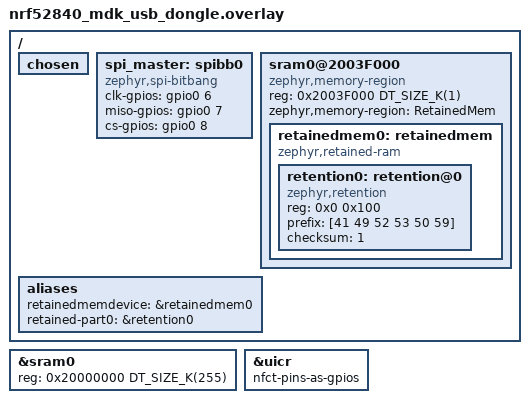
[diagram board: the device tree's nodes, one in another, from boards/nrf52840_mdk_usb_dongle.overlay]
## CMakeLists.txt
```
# Copyright (c) 2026 Arne Wendt (@bitmeal)
# SPDX-License-Identifier: MPL-2.0

cmake_minimum_required(VERSION 3.20.0)

### Zephyr
find_package(Zephyr REQUIRED HINTS $ENV{ZEPHYR_BASE})

## configure project
project(sks_airspy_community)

## check if we are building with sysbuild
test_sysbuild(REQUIRED)


### APP
# app sources
target_sources(app PRIVATE src/main.c)
target_sources(app PRIVATE src/common.c)
target_sources(app PRIVATE src/resource_manager.c)
target_sources(app PRIVATE src/settings.c)
target_sources(app PRIVATE src/bluetooth.c)
target_sources(app PRIVATE src/retained.c)
target_sources(app PRIVATE src/spi.c)
target_sources(app PRIVATE src/zbus_com.c)
target_sources(app PRIVATE src/sensor.c)

if(CONFIG_AIRSPY_ANT)
    target_sources(app PRIVATE src/ant.c)

    # ant tpms profile sources
    target_sources(app PRIVATE src/ant_profiles/ant_tpms/ant_tpms.c)
    target_sources(app PRIVATE src/ant_profiles/ant_tpms/pages/ant_tpms_page_1.c)
    target_sources(app PRIVATE src/ant_profiles/ant_tpms/pages/ant_tpms_page_16.c)
    target_sources(app PRIVATE src/ant_profiles/ant_common/pages/ant_common_page_82.c)
endif()

## include paths
target_include_directories(app PRIVATE include/)
zephyr_library_include_directories(.)
```

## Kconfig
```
# Copyright (c) 2026 Arne Wendt (@bitmeal)
# SPDX-License-Identifier: MPL-2.0


config AIRSPY_DEFAULTS
    bool
    default y
    select HW_ID_LIBRARY
    select PM_DEVICE
    select PM_DEVICE_RUNTIME
    # select POWEROFF
    select ZBUS
    select GPIO
    select SPI
    select SPI_BITBANG
    select RTC
    select RTC_EMUL
    select NVS
    select CRC
    select SETTINGS
    select SETTINGS_RUNTIME
    select MPU_ALLOW_FLASH_WRITE
    select RETENTION
    select RETAINED_MEM
    select RETAINED_MEM_ZEPHYR_RAM


if AIRSPY_DEFAULTS

choice HW_ID_LIBRARY_SOURCE
    default HW_ID_LIBRARY_SOURCE_DEVICE_ID
endchoice

choice SETTINGS_BACKEND
    default SETTINGS_NVS
endchoice

config NCS_APPLICATION_BOOT_BANNER_STRING
    default "AIRSPY Community"

config RESET_ON_FATAL_ERROR
    default n

config BOARD_SERIAL_BACKEND_CDC_ACM
    default n

config SPI_NRFX
    default n

endif # AIRSPY_DEFAULTS

# ---

config AIRSPY_SIZE_OPTIMIZATIONS
    bool
    default y

if AIRSPY_SIZE_OPTIMIZATIONS

choice COMPILER_OPTIMIZATIONS
    default SIZE_OPTIMIZATIONS
endchoice

config BT_USER_PHY_UPDATE
    default n

config BT_PHY_UPDATE
    default n

config NET_BUF_POOL_USAGE
    default n

config LOG_RUNTIME_FILTERING
    default n
    
endif # AIRSPY_SIZE_OPTIMIZATIONS

# ---

config AIRSPY_ANT
    bool "enable ANT communiction; disable for debugging or development if no ANT SDK is available"
    default y
    select ANT
    select ANT_EVALUATION_KEY
    select ANT_CHANNEL_CONFIG
    select ANT_KEY_MANAGER
    select ANT_COMMON

if AIRSPY_ANT

config HEAP_MEM_POOL_SIZE
    default 2048
    # default 4096

config ANT_TOTAL_CHANNELS_ALLOCATED
    default 1

endif # AIRSPY_ANT

# ---

config AIRSPY_DFU_COMPAT_PADDING
    bool "0x400 pm static mcuboot padding"
    default y
    help
        force compatibility with previously set values in pm_static.yml
        allows OTA DFU of devices using MCUboot variants build from partition manager configuration

if AIRSPY_DFU_COMPAT_PADDING

config ROM_START_OFFSET
	default 0x400 if BOOTLOADER_MCUBOOT && USE_DT_CODE_PARTITION

endif # AIRSPY_DFU_COMPAT_PADDING

# TODO: BT dependency

config AIRSPY_DFU
    bool
    default y
    select MPU_ALLOW_FLASH_WRITE
    select MCUMGR
    select FLASH
    select STREAM_FLASH
    select FLASH_MAP
    select NET_BUF
    select ZCBOR
    select IMG_MANAGER
    select MCUMGR
    select MCUMGR_MGMT_NOTIFICATION_HOOKS
    select MCUMGR_GRP_IMG
    select MCUMGR_GRP_IMG_STATUS_HOOKS
    select MCUMGR_GRP_IMG_SLOT_INFO
    select MCUMGR_GRP_OS
    select MCUMGR_GRP_OS_MCUMGR_PARAMS
    select MCUMGR_GRP_OS_ECHO
    select MCUMGR_GRP_OS_INFO
    select MCUMGR_GRP_OS_DATETIME
    select MCUMGR_GRP_OS_DATETIME_MS
    select MCUMGR_GRP_OS_BOOTLOADER_INFO
    # select MCUMGR_GRP_OS_INFO_BUILD_DATE_TIME
    select MCUMGR_GRP_ENUM
    select MCUMGR_GRP_ENUM_DETAILS
    select MCUMGR_GRP_ENUM_DETAILS_NAME
    select MCUMGR_GRP_SETTINGS
    select MCUMGR_GRP_SETTINGS_ACCESS_HOOK
    select MCUMGR_TRANSPORT_BT
    select MCUMGR_TRANSPORT_BT_CONN_PARAM_CONTROL
    select MCUMGR_TRANSPORT_BT_REASSEMBLY

if AIRSPY_DFU

config BT_L2CAP_TX_MTU
    default 498

config BT_BUF_ACL_RX_SIZE
    default 502

config BT_BUF_ACL_TX_SIZE
    default 502

config BT_CTLR_DATA_LENGTH_MAX
    default 251

config MCUMGR_GRP_ZBASIC_STORAGE_ERASE
    default n

config MCUMGR_TRANSPORT_NETBUF_SIZE
    default 2475

config MCUMGR_TRANSPORT_WORKQUEUE_STACK_SIZE
    default 4608

# set high to transfer signature keys as settings
config MCUMGR_GRP_SETTINGS_VALUE_LEN
    default 512

config MAIN_STACK_SIZE
    default 2176
    # default 2048
config SYSTEM_WORKQUEUE_STACK_SIZE
    default 2304

endif # AIRSPY_DFU

# ---

config AIRSPY_BT
    bool
    default y
    select BT
    select BT_DEVICE_NAME_DYNAMIC
    select BT_PERIPHERAL
    select BT_DIS
    select BT_DIS_MODEL_NUMBER
    select BT_DIS_MANUF_NAME
    # select BT_DIS_SERIAL_NUMBER
    select BT_DIS_FW_REV
    # select BT_DIS_HW_REV
    select BT_DIS_SW_REV
    select BT_BAS

if AIRSPY_BT

config BT_DEVICE_NAME
    default "AIRSPY Community"

config BT_DEVICE_NAME_MAX
    default 23

config BT_DEVICE_APPEARANCE
    # 0x0559 / 1369 Vehicle Tire Pressure Sensor
    # 0x0480 / 1152 Generic Cycling
    default 1152

config BT_DIS_PNP
    default n

config BT_DIS_MODEL_NUMBER_STR
    default "Airspy"

config BT_DIS_MANUF_NAME_STR
    default "SKS"

# config BT_DIS_SERIAL_NUMBER_STR
#     default "Zephyr Serial"

config BT_DIS_FW_REV_STR
    default "Zephyr"

# config BT_DIS_HW_REV_STR
#     default "Zephyr Hardware"

config BT_DIS_SW_REV_STR
    default "Community"

config BT_MAX_CONN
    default 1

config BT_CTLR_LE_PING
    default n

endif # AIRSPY_BT

# ---
# TODO: depends RTT
# TODO: depends BT
# TODO: enable log, or enable log by enabling individual backends?

config AIRSPY_LOG
    bool
    default y
    select LOG
    select LOG_BACKEND_BLE
    select LOG_BACKEND_RTT
    select USE_SEGGER_RTT

if AIRSPY_LOG

choice LOG_MODE
    default LOG_MODE_DEFERRED
endchoice

# NUS logging requirement
config LOG_PROCESS_THREAD_STACK_SIZE
    default 2048

# disable duplicate log messages on RTT
config LOG_BACKEND_UART
    default n

endif # AIRSPY_LOG

# ---

source "Kconfig.zephyr"
```

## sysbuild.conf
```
# Copyright (c) 2026 Arne Wendt (@bitmeal)
# SPDX-License-Identifier: MPL-2.0

## MCUBoot bootloader config
SB_CONFIG_BOOTLOADER_MCUBOOT=y
SB_CONFIG_MCUBOOT_MODE_SWAP_USING_MOVE=y
# SB_CONFIG_BOOT_SIGNATURE_TYPE_RSA=y
# SB_CONFIG_BOOT_SIGNATURE_KEY_FILE="\${APP_DIR}/mcuboot.pem"

## build system configuration
# use partitions from device tree fstab.dtsi
SB_CONFIG_PARTITION_MANAGER=n

SB_CONFIG_WARN_EXPERIMENTAL=n

## output artifacts
SB_CONFIG_DFU_ZIP=y
# # generate merged.hex; currently broken in v3.2.4 with sysbuild; workaround in ./sysbuild/CMakeLists.txt
# SB_CONFIG_MERGED_HEX_FILES=y
```

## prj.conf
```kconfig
# Copyright (c) 2026 Arne Wendt (@bitmeal)
# SPDX-License-Identifier: MPL-2.0

CONFIG_WARN_EXPERIMENTAL=n
```

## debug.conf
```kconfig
# Copyright (c) 2026 Arne Wendt (@bitmeal)
# SPDX-License-Identifier: MPL-2.0

# CONFIG_AIRSPY_ANT=n

CONFIG_THREAD_NAME=y
CONFIG_THREAD_STACK_INFO=y
CONFIG_DEBUG=y
CONFIG_DEBUG_THREAD_INFO=y

## does not fit in flash with ANT stack
# CONFIG_DEBUG_OPTIMIZATIONS=y
```

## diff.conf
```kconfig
CONFIG_LOG=y
CONFIG_MCUBOOT_GENERATE_UNSIGNED_IMAGE=y
CONFIG_NCS_MCUBOOT_IN_BUILD=y
CONFIG_BOOTLOADER_MCUBOOT=y
CONFIG_USE_SEGGER_RTT=y
CONFIG_BOARD_HAS_NRF5_BOOTLOADER=n
CONFIG_GPIO_AS_PINRESET=y
CONFIG_NFCT_PINS_AS_GPIOS=y
CONFIG_RTT_CONSOLE=y
CONFIG_LOG_BACKEND_UART=n
```

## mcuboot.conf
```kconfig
# CONFIG_BOOT_VALIDATE_SLOT0=n

# crypto
# default (mbedtls)
# CONFIG_BOOT_SIGNATURE_TYPE_RSA=y
# tinycrypt:
# CONFIG_BOOT_SIGNATURE_TYPE_ECDSA_P256=y
# CONFIG_BOOT_SIGNATURE_TYPE_NONE=y

# 512kB flash; two images (each < 256kB); sector size 0x1000 / 4096B
# CONFIG_BOOT_MAX_IMG_SECTORS=64
# 52840 devel board
CONFIG_BOOT_MAX_IMG_SECTORS=128

# mcuboot
CONFIG_MCUBOOT_SERIAL=n

# peripherals/IO
CONFIG_GPIO=n
CONFIG_SERIAL=n
CONFIG_USE_SEGGER_RTT=n
CONFIG_CONSOLE=n
CONFIG_UART_CONSOLE=n
CONFIG_RTT_CONSOLE=n

# logging
CONFIG_LOG=n
CONFIG_BOOT_BANNER=n
CONFIG_MCUBOOT_BOOT_BANNER=n
CONFIG_NCS_BOOT_BANNER=n
```

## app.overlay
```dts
/*
 * Copyright (c) 2026 Arne Wendt (@bitmeal)
 * SPDX-License-Identifier: MPL-2.0
 */

 / {
    chosen {
        /delete-property/ zephyr,code-partition;
        zephyr,code-partition = &slot0_partition;

        /delete-property/ zephyr,console;
		zephyr,console = &rtt0;
    };

	rtt0: rtt_chan0 {
		compatible = "segger,rtt-uart";
		status = "okay";
	};

    rtc_emul: rtc-emul {
		compatible = "zephyr,rtc-emul";
		alarms-count = < 1 >;
	};

	aliases {
		rtc = &rtc_emul;
	};
};

// Include flash partition table.
#include "fstab.dtsi"
```

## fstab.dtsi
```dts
/*
 * Copyright (c) 2026 Arne Wendt (@bitmeal)
 * SPDX-License-Identifier: MPL-2.0
 */

&flash0 {
    /delete-node/ partitions;
};

&flash0 {
    partitions {
        compatible = "fixed-partitions";
        #address-cells = <1>;
        #size-cells = <1>;

        boot_partition: partition@0 {
            label = "mcuboot";
            reg = <0x00000000 0x00006000>;
            read-only;
        };

        slot0_partition: partition@6000 {
            label = "image-0";
            reg = <0x00006000 0x0003c000>;
        };
		
        slot1_partition: partition@42000 {
            label = "image-1";
            reg = <0x00042000 0x0003c000>;
        };

        storage_partition: partition@7e000 {
            label = "storage";
            reg = <0x0007e000 0x00002000>;
        };
    };
};
```

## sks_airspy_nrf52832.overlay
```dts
/*
 * Copyright (c) 2025 Arne Wendt (@bitmeal)
 * SPDX-License-Identifier: MPL-2.0
 */

// / {
// 	spi_master: spibb0 {
// 		compatible = "zephyr,spi-bitbang";
// 		status = "okay";
		
// 		#address-cells = <1>;
// 		#size-cells = <0>;
	
// 		clk-gpios = <&gpio0 19 GPIO_ACTIVE_HIGH>;
// 		miso-gpios = <&gpio0 15 0>;

// 		// interrupt pin
// 		cs-gpios = <&gpio0 22 GPIO_ACTIVE_LOW>;
// 	};
// };

// / {
//     chosen {
//         /* Directs Zephyr to link your application text section to the primary slot */
//         zephyr,code-partition = &slot0_partition;
//         // zephyr,code-partition = &slot0_app_partition;
//     };
// };

// &flash0 {
//     /delete-node/ partitions;
// };

// &flash0 {
//     partitions {
//         compatible = "fixed-partitions";
//         #address-cells = <1>;
//         #size-cells = <1>;

//         /* 0x00000 to 0x06000: MCUboot Bootloader (24 KB) */
//         boot_partition: partition@0 {
//             label = "mcuboot";
//             reg = <0x00000000 0x00006000>;
//             read-only;
//         };

//         /* 0x06000 to 0x42000: Primary Slot (240 KB total) */
//         slot0_partition: partition@6000 {
//             label = "image-0";
//             reg = <0x00006000 0x0003c000>;
//         };
		
		
//         // /* 0x06400 to 0x42000: Primary Slot App  */
// 		// slot0_app_partition: partition@6400 {
//         //     label = "image-0-app";
//         //     reg = <0x00006400 0x0003bc00>;
//         // };

//         /* 0x42000 to 0x7E000: Secondary Upgrade Slot (240 KB total) */
//         slot1_partition: partition@42000 {
//             label = "image-1";
//             reg = <0x00042000 0x0003c000>;
//         };

//         /* 0x7E000 to 0x80000: Zephyr Settings Subsystem Storage (8 KB) */
//         storage_partition: partition@7e000 {
//             label = "storage";
//             reg = <0x0007e000 0x00002000>;
//         };
//     };
// };
```

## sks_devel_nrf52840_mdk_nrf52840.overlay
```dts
/*
 * Copyright (c) 2025 Arne Wendt (@bitmeal)
 * SPDX-License-Identifier: MPL-2.0
 */

/ {
	spi_master: spibb0 {
		compatible = "zephyr,spi-bitbang";
		status = "okay";
		
		#address-cells = <1>;
		#size-cells = <0>;
	
		clk-gpios = <&gpio0 6 GPIO_ACTIVE_HIGH>;
		miso-gpios = <&gpio0 7 0>;

		// interrupt pin
		cs-gpios = <&gpio0 8 GPIO_ACTIVE_LOW>;
	};
};
```

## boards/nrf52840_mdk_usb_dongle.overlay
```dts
/*
 * Copyright (c) 2026 Arne Wendt (@bitmeal)
 * SPDX-License-Identifier: MPL-2.0
 */

/ {
	chosen {
		// /delete-property/ zephyr,console;
		// zephyr,console = &rtt0;

		// /delete-property/ zephyr,code-partition;
        	// zephyr,code-partition = &slot0_partition;
	};

	spi_master: spibb0 {
		compatible = "zephyr,spi-bitbang";
		status = "okay";

		#address-cells = <1>;
		#size-cells = <0>;

		clk-gpios = <&gpio0 6 GPIO_ACTIVE_HIGH>;
		miso-gpios = <&gpio0 7 GPIO_ACTIVE_HIGH>;

		// interrupt pin:
		// depending on model, active high or low! configured at runtime
		cs-gpios = <&gpio0 8 GPIO_ACTIVE_HIGH>;
	};

	sram0@2003F000 {
		compatible = "zephyr,memory-region", "mmio-sram";
		reg = <0x2003F000 DT_SIZE_K(1)>;
		zephyr,memory-region = "RetainedMem";
		status = "okay";

		retainedmem0: retainedmem  {
			compatible = "zephyr,retained-ram";
			status = "okay";

                        #address-cells = <1>;
                        #size-cells = <1>;

			retention0: retention@0 {
				compatible = "zephyr,retention";
				status = "okay";
				reg = <0x0 0x100>;
                                prefix = [41 49 52 53 50 59]; // AIRSPY
                                checksum = <1>;
			};
		};
	};


	aliases {
		retainedmemdevice = &retainedmem0;
		retained-part0 = &retention0;
	};

};

&sram0 {
	reg = <0x20000000 DT_SIZE_K(255)>;
};

&uicr {
	nfct-pins-as-gpios;
};

// Include flash partition table.
#include "../fstab.dtsi"
```

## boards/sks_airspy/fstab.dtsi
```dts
/*
 * Copyright (c) 2025 Arne Wendt (@bitmeal)
 * SPDX-License-Identifier: MPL-2.0
 */


/* Flash partition table for use with MCUBoot */
// &flash0 {
// 	partitions {
// 		compatible = "fixed-partitions";
// 		#address-cells = <1>;
// 		#size-cells = <1>;

// 		boot_partition: partition@0 {
// 			label = "mcuboot";
// 			reg = <0x00000000 0x6000>;
// 		};
// 		slot0_partition: partition@6000 {
// 			label = "image-0";
// 			reg = <0x00006000 0x3D000>;
// 		};
// 		slot1_partition: partition@43000 {
// 			label = "image-1";
// 			reg = <0x00043000 0x3D000>;
// 		};
// 	};
// };

&flash0 {
    partitions {
        compatible = "fixed-partitions";
        #address-cells = <1>;
        #size-cells = <1>;

        boot_partition: partition@0 {
            label = "mcuboot";
            reg = <0x00000000 0x00006000>;
            read-only;
        };

        slot0_partition: partition@6000 {
            label = "image-0";
            reg = <0x00006000 0x0003c000>;
        };
		
        slot1_partition: partition@42000 {
            label = "image-1";
            reg = <0x00042000 0x0003c000>;
        };

        storage_partition: partition@7e000 {
            label = "storage";
            reg = <0x0007e000 0x00002000>;
        };
    };
};
```

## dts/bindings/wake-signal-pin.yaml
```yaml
# Copyright (c) 2025 Arne Wendt (@bitmeal)
# SPDX-License-Identifier: MPL-2.0

description: GPIO pin to wake up controller from low power mode

compatible: "wake-signal-pin"

properties:
  gpios:
    type: phandle-array
    required: true
    description: |
      The GPIO connected to the wake up signal source.
```

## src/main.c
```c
/*
 * Copyright (c) 2026 Arne Wendt (@bitmeal)
 * SPDX-License-Identifier: MPL-2.0
 */

#include <stdlib.h>
#include <zephyr/kernel.h>

#include <zephyr/device.h>
#include <zephyr/devicetree.h>
#include <zephyr/drivers/gpio.h>

#include <zephyr/drivers/hwinfo.h>
#include <zephyr/pm/device.h>

#include <zephyr/mgmt/mcumgr/mgmt/mgmt.h>
#include <zephyr/mgmt/mcumgr/mgmt/callbacks.h>

#include <zephyr/logging/log.h>
LOG_MODULE_REGISTER(main, LOG_LEVEL_INF);

#include "retained.h"
#include "settings.h"

#include "bluetooth.h"
#if CONFIG_AIRSPY_ANT
#include "ant.h"
#endif
#include "spi.h"
#include "resource_manager.h"


#define SUPERVISION_CYCLE_TIME_MS 1000

static void supervise(struct k_work *work);
K_WORK_DELAYABLE_DEFINE(supervision_work, supervise);

static void end_bt_keepalive(struct k_work *work);
K_WORK_DELAYABLE_DEFINE(end_bt_keepalive_work, end_bt_keepalive);


static void supervise(struct k_work *work)
{
	retained_update();
	// dummy supervision
	k_work_schedule(&supervision_work, K_MSEC(SUPERVISION_CYCLE_TIME_MS));
}

static void end_bt_keepalive(struct k_work *work)
{
	res_mgr_free(&res_mgr_BT);
}

int main(void)
{
	// /* using __TIME__ ensure that a new binary will be built on every
	//  * compile which is convenient when testing firmware upgrade.
	//  */
	// LOG_INF("build time: " __DATE__ " " __TIME__);
	
	///////////////////////////////////////////
	LOG_INF("reading BOOT state...");

	retained_init();
    retained.uptime_latest = 0;
	retained.boots += 1;
	retained_update();

	LOG_INF("boot count: %u; uptime sum: %llus", retained.boots, retained.uptime_sum);

	///////////////////////////////////////////
	LOG_INF("initializing settings storage...");
	start_settings_subsys();

	///////////////////////////////////////////
	LOG_INF("initializing bluetooth...");
	init_bluetooth();
	
	LOG_INF("using resource: BT");
	res_mgr_use(&res_mgr_BT);
	k_work_schedule(&end_bt_keepalive_work, K_MSEC(app_config.device.bt_timeout_ms));

	///////////////////////////////////////////
#if CONFIG_AIRSPY_ANT
	LOG_INF("starting ANT+ device...");
	init_ant();
#endif

	///////////////////////////////////////////
	LOG_INF("starting SPI sensor interface...");
	init_spim();

	///////////////////////////////////////////
	// wait for subsystems to start operation
	k_sleep(K_MSEC(2000));
	// supervise system
	LOG_INF("Scheduling application supervision");
	k_work_schedule(&supervision_work, K_MSEC(SUPERVISION_CYCLE_TIME_MS));

	///////////////////////////////////////////
	return EXIT_SUCCESS;
}
```

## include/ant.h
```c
/*
 * Copyright (c) 2026 Arne Wendt (@bitmeal)
 * SPDX-License-Identifier: MPL-2.0
 */

#ifndef INCLUDE_APP_ANT_H__
#define INCLUDE_APP_ANT_H__

#include <zephyr/zbus/zbus.h>


#define SCHEDULE_PAGE16_BACKOFF_MS 250

int init_ant(void);

void ant_sensor_data_handler_cb(const struct zbus_channel *chan);
void ant_config_update_notification_handler_cb(const struct zbus_channel *chan);

#endif // INCLUDE_APP_ANT_H__
```

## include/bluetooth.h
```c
/*
 * Copyright (c) 2026 Arne Wendt (@bitmeal)
 * SPDX-License-Identifier: MPL-2.0
 */

#ifndef INCLUDE_BLUETOOTH_H__
#define INCLUDE_BLUETOOTH_H__

#include <zephyr/bluetooth/uuid.h>
#include <zephyr/zbus/zbus.h>


void init_bluetooth(void);

void ble_sensor_data_handler_cb(const struct zbus_channel *chan);
void ble_config_update_notification_handler_cb(const struct zbus_channel *chan);

#endif // INCLUDE_BLUETOOTH_H__
```

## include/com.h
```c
// #ifndef INCLUDE_COM_H__
// #define INCLUDE_COM_H__

// extern struct k_msgq spi_ant_queue;

// #endif // INCLUDE_COM_H__
```

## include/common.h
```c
/*
 * Copyright (c) 2025 Arne Wendt (@bitmeal)
 * SPDX-License-Identifier: MPL-2.0
 */

#ifndef INCLUDE_COMMON_H__
#define INCLUDE_COMMON_H__

#include <stdint.h>

uint16_t get_hwid_16bit();

#endif // INCLUDE_COMMON_H__
```

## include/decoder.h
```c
#ifndef INCLUDE_DECODER_H__
#define INCLUDE_DECODER_H__

#include <stdlib.h>
#include <stdint.h>

#define SENSOR_BUFFER_SIZE 6

struct __attribute__((__packed__)) sensor_readings_t {
    int16_t pressure_hpa;
    int8_t temperature_c;
    int16_t voltage_mv;
    unsigned char flags;
    unsigned char checksum;
};

#define SENSOR_COMP_CONST_PRESS 17
#define SENSOR_COMP_CONST_TEMP -55
#define SENSOR_COMP_CONST_VOLT 122

#define SENSOR_FLAG_UNDERVOLTAGE = 0x20

#define SENSOR_ERROR_CHK 1

int decode_sensor_buffer(uint8_t* buffer, struct sensor_readings_t* sensor_readings);

#endif // INCLUDE_DECODER_H__
```

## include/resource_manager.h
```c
/*
 * Copyright (c) 2026 Arne Wendt (@bitmeal)
 * SPDX-License-Identifier: MPL-2.0
 */

#ifndef INCLUDE_RESOURCE_MANAGER_H__
#define INCLUDE_RESOURCE_MANAGER_H__

#include <zephyr/sys/atomic.h>

extern atomic_t res_mgr_BT;
extern atomic_t res_mgr_ANT;

void res_mgr_use(atomic_t * res);
void res_mgr_free(atomic_t * res);
bool res_mgr_in_use(atomic_t * res);

#endif // INCLUDE_RESOURCE_MANAGER_H__
```

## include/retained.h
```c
/*
 * Copyright (c) 2026 Arne Wendt (@bitmeal)
 * SPDX-License-Identifier: MPL-2.0
 */

#ifndef INCLUDE_RETAINED_H__
#define INCLUDE_RETAINED_H__

#include <stdbool.h>
#include <stdint.h>

struct retained_data {
	// last update of retained data
	uint64_t uptime_latest;
	// cumulative uptime up to uptime_latest
	uint64_t uptime_sum;
	uint32_t boots;
	uint32_t crc;
};


extern struct retained_data retained;

void retained_init();
void retained_update();

#endif // INCLUDE_RETAINED_H__
```

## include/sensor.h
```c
/*
 * Copyright (c) 2025 Arne Wendt (@bitmeal)
 * SPDX-License-Identifier: MPL-2.0
 */

#ifndef INCLUDE_SENSOR_H__
#define INCLUDE_SENSOR_H__

#include <stdlib.h>
#include <stdint.h>

#define SENSOR_BUFFER_SIZE 6

/*
layout:
    [0, 17): pressure --> b[9:17].int * 16.75 - 248
    [17, 25) - 55 ^= temperature
    [25, 33) + 122 ^= voltage
    35: FLAG: under voltage
    [40,48): XOR checksum; ignore lowest bit after shifting whole buffer
*/

struct __attribute__((__packed__)) sensor_readings_t {
    int16_t pressure_hpa;
    int8_t temperature_c;
    int16_t voltage_mv;
    unsigned char flags;
    unsigned char checksum;
};

#define SENSOR_CLAMP_PRESS_LOW_HPA 75
#define SENSOR_COMP_CONST_PRESS_SLOPE 16.75
#define SENSOR_COMP_CONST_PRESS_OFFSET -248
#define SENSOR_COMP_CONST_TEMP -55
#define SENSOR_COMP_CONST_VOLT 122

#define SENSOR_FLAG_UNDERVOLTAGE = 0x20

#define SENSOR_ERROR_CHK 1

int decode_sensor_buffer(uint8_t* buffer, struct sensor_readings_t* sensor_readings);
uint8_t battery_level_percent(const int16_t voltage_mv);

#endif // INCLUDE_SENSOR_H__
```

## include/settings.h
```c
/*
 * Copyright (c) 2026 Arne Wendt (@bitmeal)
 * SPDX-License-Identifier: MPL-2.0
 */

#ifndef INCLUDE_SETTINGS_H__
#define INCLUDE_SETTINGS_H__


#include <stdbool.h>
#include <zephyr/settings/settings.h>
#include <ant_profiles/tpms/ant_tpms_common_types.h>


#define TPMS_CONFIG_ROLE_DEFAULT                    ANT_TPMS_ROLE_NONE
#define TPMS_CONFIG_AMBIENT_COMPENSATION_DEFAULT    1013
#define TPMS_CONFIG_ALARM_DEFAULT                   0xffff
#define TPMS_CONFIG_TYPE_DEFAULT                    0x03
#define TPMS_CONFIG_PADDING_DEFAULT                 0xff

#define DEVICE_CONFIG_BT_TIMEOUT_DEFAULT            30000

#define APP_CONFIG_VERSION 1        // /ver        

typedef enum
{
    CONFIG_UPDATE_SOURCE_EMPTY      = 0x00,
    CONFIG_UPDATE_SOURCE_SETTINGS   = 0x01,
    CONFIG_UPDATE_SOURCE_ANT        = 0x02,
    CONFIG_UPDATE_SOURCE_BLE        = 0x04,
} config_update_source_t;

typedef enum
{
    DEVICE_SPI_POLARITY_UNCONFIGURED    = 0x00,
    DEVICE_SPI_POLARITY_RISING          = 0x01,
    DEVICE_SPI_POLARITY_FALLING         = 0x02,
} device_spi_polarity_t;


typedef struct {
    uint8_t  role;                              // /tpms/role
    uint16_t ambient_compensation;              // /tpms/ambcomp
    uint16_t ambient_compensation_dynamic;      // NOT PERSISTENT
    bool     ambient_compensation_is_dynamic;   // NOT PERSISTENT
    uint16_t alarm_low;                         // /tpms/alarm/low
    uint16_t alarm_high;                        // /tpms/alarm/high
    uint8_t  type;                              // /tpms/type
    uint8_t  padding;                           // /tpms/padding
} tpms_config_t;

typedef struct {
    uint16_t id;                    // /dev/id
    uint64_t bt_timeout_ms;         // /dev/bt_timeout
    uint8_t spi_polarity;         // /dev/spi_polarity (device_spi_polarity_t)
} device_config_t;

typedef struct {
    tpms_config_t tpms;
    device_config_t device;
} app_config_t;

extern app_config_t app_config;

int start_settings_subsys();
int settings_commit_notify(config_update_source_t source);
void log_settings();

#endif // INCLUDE_SETTINGS_H__
```

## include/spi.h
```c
/*
 * Copyright (c) 2025 Arne Wendt (@bitmeal)
 * SPDX-License-Identifier: MPL-2.0
 */

#ifndef INCLUDE_SPI_H__
#define INCLUDE_SPI_H__

#include <zephyr/drivers/gpio.h>
#include <zephyr/zbus/zbus.h>
#include "settings.h"

// start polarity learning with falling edge trigger
#define DEVICE_SPI_POLARITY_STARTUP DEVICE_SPI_POLARITY_FALLING
#define DEVICE_SPI_POLARITY_SUCCESS_COUNT 10

int init_spim();

void spi_config_update_notification_handler_cb(const struct zbus_channel *chan);


#endif // INCLUDE_SPI_H__
```

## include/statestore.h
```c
/*
 * Copyright (c) 2026 Arne Wendt (@bitmeal)
 * SPDX-License-Identifier: MPL-2.0
 */

#ifndef INCLUDE_STATESTORE_H__
#define INCLUDE_STATESTORE_H__

#include <stdlib.h>
#include <stdint.h>

// decoded and compensated sensor environmental readings
typedef struct {

} sensor_state_t;

// compensation values; alarm thresholds
typedef struct {

} sensor_config_t;

// boot count, uptime, voltage
typedef struct {

} device_state_t;

// ID, role
typedef struct {

} device_config_t;

typedef struct {
    sensor_state_t sensor_state;
    sensor_config_t sensor_config;
    device_state_t device_state;
    device_config_t device_config;
} state_store_t;

#endif // INCLUDE_STATESTORE_H__
```

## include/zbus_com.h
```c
/*
 * Copyright (c) 2025 Arne Wendt (@bitmeal)
 * SPDX-License-Identifier: MPL-2.0
 */

#ifndef INCLUDE_ZBUS_COM_H__
#define INCLUDE_ZBUS_COM_H__

#include <zephyr/zbus/zbus.h>
#include "settings.h"


ZBUS_CHAN_DECLARE(sensor_data_chan);
ZBUS_CHAN_DECLARE(config_update_notification_chan);

#endif // INCLUDE_ZBUS_COM_H__
```
